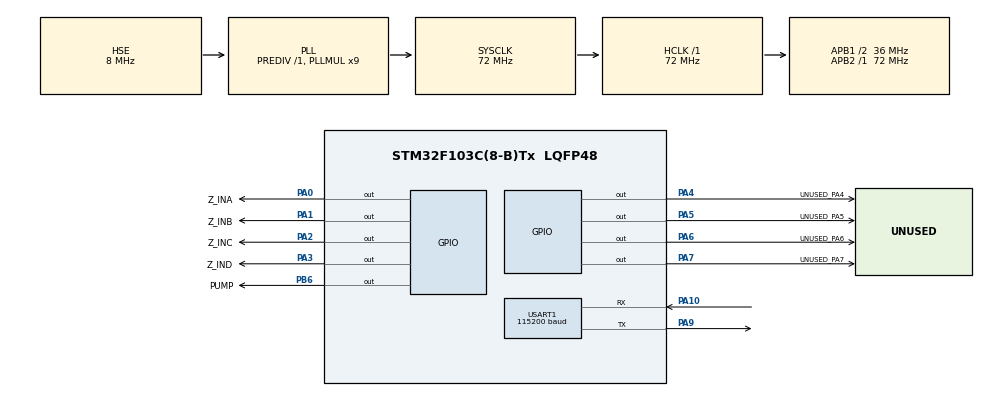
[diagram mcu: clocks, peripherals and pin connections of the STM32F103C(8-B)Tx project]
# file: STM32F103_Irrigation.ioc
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Mcu.Family=STM32F1
Mcu.Name=STM32F103C(8-B)Tx
Mcu.Package=LQFP48
NVIC.PriorityGroup=NVIC_PRIORITYGROUP_4
NVIC.USART1_IRQn=true\:0\:0\:false\:false\:true\:true\:true
PA0-WKUP.GPIO_Label=Z_INA
PA0-WKUP.Signal=GPIO_Output
PA1.GPIO_Label=Z_INB
PA1.Signal=GPIO_Output
PA10.Mode=Asynchronous
PA10.Signal=USART1_RX
PA13.Mode=Serial_Wire
PA13.Signal=SYS_JTMS-SWDIO
PA14.Mode=Serial_Wire
PA14.Signal=SYS_JTCK-SWCLK
PA2.GPIO_Label=Z_INC
PA2.Signal=GPIO_Output
PA3.GPIO_Label=Z_IND
PA3.Signal=GPIO_Output
PA4.GPIO_Label=UNUSED_PA4
PA4.Signal=GPIO_Output
PA5.GPIO_Label=UNUSED_PA5
PA5.Signal=GPIO_Output
PA6.GPIO_Label=UNUSED_PA6
PA6.Signal=GPIO_Output
PA7.GPIO_Label=UNUSED_PA7
PA7.Signal=GPIO_Output
PA9.Mode=Asynchronous
PA9.Signal=USART1_TX
PB6.GPIO_Label=PUMP
PB6.GPIO_ModeDefaultOutputPP=GPIO_MODE_OUTPUT_OD
PB6.PinState=GPIO_PIN_SET
PB6.Signal=GPIO_Output
PD0-OSC_IN.Mode=HSE-External-Oscillator
PD0-OSC_IN.Signal=RCC_OSC_IN
PD1-OSC_OUT.Mode=HSE-External-Oscillator
PD1-OSC_OUT.Signal=RCC_OSC_OUT
ProjectManager.HeapSize=0x200
ProjectManager.StackSize=0x400
ProjectManager.TargetToolchain=MDK-ARM V5.32
RCC.ADCPresc=RCC_ADCPCLK2_DIV6
RCC.AHBFreq_Value=72000000
RCC.APB1CLKDivider=RCC_HCLK_DIV2
RCC.APB1Freq_Value=36000000
RCC.APB1TimFreq_Value=72000000
RCC.APB2Freq_Value=72000000
RCC.APB2TimFreq_Value=72000000
RCC.HCLKFreq_Value=72000000
RCC.PLLMUL=RCC_PLL_MUL9
RCC.PLLSourceVirtual=RCC_PLLSOURCE_HSE
RCC.SYSCLKFreq_VALUE=72000000
RCC.SYSCLKSource=RCC_SYSCLKSOURCE_PLLCLK
RCC.USBFreq_Value=48000000
RCC.USBPrescaler=RCC_USBCLKSOURCE_PLL_DIV1_5
USART1.BaudRate=115200
USART1.VirtualMode=VM_ASYNC
board=custom

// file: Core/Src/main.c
/* USER CODE BEGIN Header */
/**
  ******************************************************************************
  * @file           : main.c
  * @brief          : Main program body
  ******************************************************************************
  * @attention
  *
  * <h2><center>&copy; Copyright (c) 2026 STMicroelectronics.
  * All rights reserved.</center></h2>
  *
  * This software component is licensed by ST under BSD 3-Clause license,
  * the "License"; You may not use this file except in compliance with the
  * License. You may obtain a copy of the License at:
  *                        opensource.org/licenses/BSD-3-Clause
  *
  ******************************************************************************
  */
/* USER CODE END Header */
#include "main.h"
#include "usart.h"
#include "gpio.h"

/* USER CODE BEGIN Includes */
#include "app.h"
/* USER CODE END Includes */

void SystemClock_Config(void);

int main(void)
{

  /* MCU Configuration--------------------------------------------------------*/

  /* Reset of all peripherals, Initializes the Flash interface and the Systick. */
  HAL_Init();

  /* Initialize all configured peripherals */
  MX_GPIO_Init();

  /*
   * Put PB6 and all motor inputs into their inactive states before waiting for
   * the external oscillator.  This minimizes relay activity during startup.
   */
  SystemClock_Config();
  MX_USART1_UART_Init();
  /* USER CODE BEGIN 2 */
  App_Init(&huart1);
  /* USER CODE END 2 */

  /* Infinite loop */
  while (1)
  {

    /* USER CODE BEGIN 3 */
    App_Task();
  }
  /* USER CODE END 3 */
}

void SystemClock_Config(void)
{
  RCC_OscInitTypeDef RCC_OscInitStruct = {0};
  RCC_ClkInitTypeDef RCC_ClkInitStruct = {0};

  /** Initializes the RCC Oscillators according to the specified parameters
  * in the RCC_OscInitTypeDef structure.
  */
  RCC_OscInitStruct.OscillatorType = RCC_OSCILLATORTYPE_HSE;
  RCC_OscInitStruct.HSEState = RCC_HSE_ON;
  RCC_OscInitStruct.HSEPredivValue = RCC_HSE_PREDIV_DIV1;
  RCC_OscInitStruct.HSIState = RCC_HSI_ON;
  RCC_OscInitStruct.PLL.PLLState = RCC_PLL_ON;
  RCC_OscInitStruct.PLL.PLLSource = RCC_PLLSOURCE_HSE;
  RCC_OscInitStruct.PLL.PLLMUL = RCC_PLL_MUL9;
  if (HAL_RCC_OscConfig(&RCC_OscInitStruct) != HAL_OK)
  {
    /*
     * Keep the controller reachable if the external 8 MHz crystal does not
     * start.  HSI/2 x 16 gives a 64 MHz fallback clock; USART timing is then
     * calculated from the actual peripheral clock by HAL.
     */
    RCC_OscInitStruct.OscillatorType = RCC_OSCILLATORTYPE_HSE
                                    | RCC_OSCILLATORTYPE_HSI;
    RCC_OscInitStruct.HSEState = RCC_HSE_OFF;
    RCC_OscInitStruct.HSEPredivValue = RCC_HSE_PREDIV_DIV1;
    RCC_OscInitStruct.HSIState = RCC_HSI_ON;
    RCC_OscInitStruct.PLL.PLLState = RCC_PLL_ON;
    RCC_OscInitStruct.PLL.PLLSource = RCC_PLLSOURCE_HSI_DIV2;
    RCC_OscInitStruct.PLL.PLLMUL = RCC_PLL_MUL16;
    if (HAL_RCC_OscConfig(&RCC_OscInitStruct) != HAL_OK)
    {
      Error_Handler();
    }
  }
  /** Initializes the CPU, AHB and APB buses clocks
  */
  RCC_ClkInitStruct.ClockType = RCC_CLOCKTYPE_HCLK|RCC_CLOCKTYPE_SYSCLK
                              |RCC_CLOCKTYPE_PCLK1|RCC_CLOCKTYPE_PCLK2;
  RCC_ClkInitStruct.SYSCLKSource = RCC_SYSCLKSOURCE_PLLCLK;
  RCC_ClkInitStruct.AHBCLKDivider = RCC_SYSCLK_DIV1;
  RCC_ClkInitStruct.APB1CLKDivider = RCC_HCLK_DIV2;
  RCC_ClkInitStruct.APB2CLKDivider = RCC_HCLK_DIV1;

  if (HAL_RCC_ClockConfig(&RCC_ClkInitStruct, FLASH_LATENCY_2) != HAL_OK)
  {
    Error_Handler();
  }
}

/* USER CODE BEGIN 4 */
void HAL_UART_RxCpltCallback(UART_HandleTypeDef *huart)
{
  App_UartRxCpltCallback(huart);
}

void HAL_UART_ErrorCallback(UART_HandleTypeDef *huart)
{
  App_UartErrorCallback(huart);
}
/* USER CODE END 4 */

void Error_Handler(void)
{
  /* USER CODE BEGIN Error_Handler_Debug */
  /* Active-low open-drain relay: release PB6 before halting on a fatal error. */
  HAL_GPIO_WritePin(PUMP_GPIO_Port, PUMP_Pin, GPIO_PIN_SET);
  __disable_irq();
  while (1)
  {
  }
  /* USER CODE END Error_Handler_Debug */
}

/************************ (C) COPYRIGHT STMicroelectronics *****END OF FILE****/
